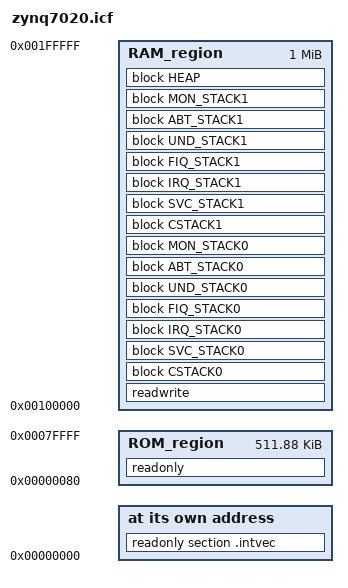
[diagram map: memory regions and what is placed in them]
/*###ICF### Section handled by ICF editor, don't touch! ****/
/*-Editor annotation file-*/
/* IcfEditorFile="$TOOLKIT_DIR$\config\ide\IcfEditor\a_tz_v1_1.xml" */
/*-Specials-*/
define symbol __ICFEDIT_intvec_start__ = 0x00000000;
/*-Memory Regions-*/
define symbol __ICFEDIT_region_ROM_start__ = 0x00000080;
define symbol __ICFEDIT_region_ROM_end__   = 0x0007FFFF;
define symbol __ICFEDIT_region_RAM_start__ = 0x00100000;
define symbol __ICFEDIT_region_RAM_end__   = 0x001FFFFF;
/*-Sizes-*/
define symbol __ICFEDIT_size_cstack__   = 0x2000;
define symbol __ICFEDIT_size_svcstack__ = 0x100;
define symbol __ICFEDIT_size_irqstack__ = 0x100;
define symbol __ICFEDIT_size_fiqstack__ = 0x100;
define symbol __ICFEDIT_size_undstack__ = 0x100;
define symbol __ICFEDIT_size_abtstack__ = 0x100;
define symbol __ICFEDIT_size_monstack__ = 0x0;
define symbol __ICFEDIT_size_heap__     = 0x8000;
/**** End of ICF editor section. ###ICF###*/

define memory mem with size = 4G;

define region ROM_region = mem:[from __ICFEDIT_region_ROM_start__ to __ICFEDIT_region_ROM_end__];
define region RAM_region = mem:[from __ICFEDIT_region_RAM_start__ to __ICFEDIT_region_RAM_end__];

do not initialize  { section .noinit };
initialize by copy { readwrite };

place at address mem:__ICFEDIT_intvec_start__ { readonly section .intvec };

place in ROM_region  { readonly };

define block CSTACK0    with alignment = 8, size = __ICFEDIT_size_cstack__   { };
define block SVC_STACK0 with alignment = 8, size = __ICFEDIT_size_svcstack__ { };
define block IRQ_STACK0 with alignment = 8, size = __ICFEDIT_size_irqstack__ { };
define block FIQ_STACK0 with alignment = 8, size = __ICFEDIT_size_fiqstack__ { };
define block UND_STACK0 with alignment = 8, size = __ICFEDIT_size_undstack__ { };
define block ABT_STACK0 with alignment = 8, size = __ICFEDIT_size_abtstack__ { };
define block MON_STACK0 with alignment = 8, size = __ICFEDIT_size_monstack__ { };

define block CSTACK1    with alignment = 8, size = __ICFEDIT_size_cstack__   { };
define block SVC_STACK1 with alignment = 8, size = __ICFEDIT_size_svcstack__ { };
define block IRQ_STACK1 with alignment = 8, size = __ICFEDIT_size_irqstack__ { };
define block FIQ_STACK1 with alignment = 8, size = __ICFEDIT_size_fiqstack__ { };
define block UND_STACK1 with alignment = 8, size = __ICFEDIT_size_undstack__ { };
define block ABT_STACK1 with alignment = 8, size = __ICFEDIT_size_abtstack__ { };
define block MON_STACK1 with alignment = 8, size = __ICFEDIT_size_monstack__ { };

define block HEAP      with alignment = 8, size = __ICFEDIT_size_heap__     { };
place in RAM_region  { readwrite,
                      block CSTACK0, block SVC_STACK0, block IRQ_STACK0, block FIQ_STACK0,
                      block UND_STACK0, block ABT_STACK0, block MON_STACK0,
                      block CSTACK1, block SVC_STACK1, block IRQ_STACK1, block FIQ_STACK1,
                      block UND_STACK1, block ABT_STACK1, block MON_STACK1,
                      block HEAP };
